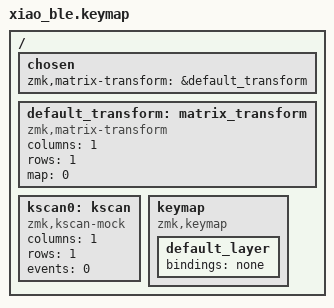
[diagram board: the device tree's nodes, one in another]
#include <behaviors.dtsi>
#include <dt-bindings/zmk/keys.h>

/ {
    /* Create a mock structural transform matrix layout */
    chosen {
        zmk,matrix-transform = &default_transform;
    };

    default_transform: matrix_transform {
        compatible = "zmk,matrix-transform";
        columns = <1>;
        rows = <1>;
        map = <0>;
    };

    /* Define a baseline 1x1 empty structural scan */
    kscan0: kscan {
        compatible = "zmk,kscan-mock";
        columns = <1>;
        rows = <1>;
        events = <0>;
    };

    keymap {
        compatible = "zmk,keymap";
        default_layer {
            bindings = <
                &none
            >;
        };
    };
};
